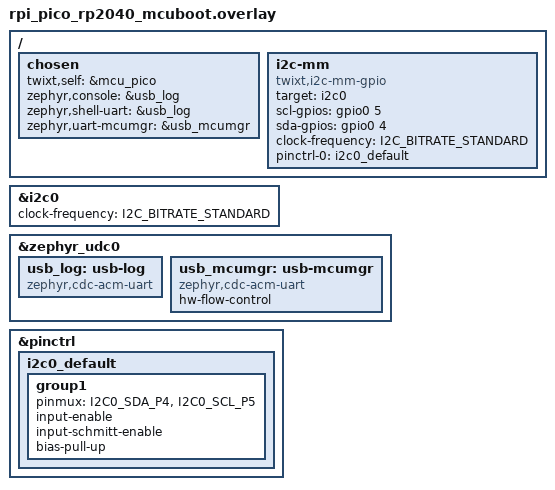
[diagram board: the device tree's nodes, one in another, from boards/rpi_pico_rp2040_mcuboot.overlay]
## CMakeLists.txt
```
# Copyright (c) 2026 Christoph Jans <jans.christoph@gmail.com>
# SPDX-License-Identifier: Apache-2.0

cmake_minimum_required(VERSION 3.20.0)

# native_sim: MCU says which one this is. Real boards: the overlay.
set(MCU pico CACHE STRING "MCU to build on native_sim: pico or nrf")
list(APPEND DTS_EXTRA_CPPFLAGS -DTWIXT_SELF_LABEL=mcu_${MCU})

find_package(Zephyr REQUIRED HINTS $ENV{ZEPHYR_BASE})
project(twixt_settings)

target_sources(app PRIVATE src/main.c)
target_sources_ifdef(CONFIG_USB_DEVICE_STACK_NEXT app PRIVATE src/usb.c)
```

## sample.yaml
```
# Copyright (c) 2026 Christoph Jans <jans.christoph@gmail.com>
# SPDX-License-Identifier: Apache-2.0

sample:
  name: Settings over twixt
common:
  tags:
    - i2c
    - settings
tests:
  # MCU a, started by twister; pytest/test_settings.py starts b next to it
  sample.twixt.settings:
    platform_allow: native_sim
    integration_platforms:
      - native_sim
    extra_args: MCU=a
    harness: pytest
    required_applications:
      - name: sample.twixt.settings.mcu_b
  sample.twixt.settings.mcu_b:
    platform_allow: native_sim
    extra_args: MCU=b
    build_only: true
  # On real boards (README): b on an nRF7002 DK, the DUT, and a on a Raspberry
  # Pico; with --device-testing, twister flashes both and pytest/test_settings.py
  # reads both logs
  sample.twixt.settings.nrf7002dk:
    platform_allow: nrf7002dk/nrf5340/cpuapp
    integration_platforms:
      - nrf7002dk/nrf5340/cpuapp
    extra_args: MCU=b
    harness: pytest
    harness_config:
      required_devices:
        - platform: rpi_pico/rp2040/mcuboot
          application: sample.twixt.settings.rpi_pico
  # a on the Pico: the image alone, signed for the MCUboot that is on the Pico
  # (README), so that the smp runner can send it over MCUmgr
  sample.twixt.settings.rpi_pico:
    platform_allow: rpi_pico/rp2040/mcuboot
    integration_platforms:
      - rpi_pico/rp2040/mcuboot
    extra_args: MCU=a
    extra_configs:
      - CONFIG_BOOTLOADER_MCUBOOT=y
      - CONFIG_MCUBOOT_BOOTLOADER_MODE_SWAP_USING_OFFSET=y
      - CONFIG_MCUBOOT_SIGNATURE_KEY_FILE="bootloader/mcuboot/root-rsa-2048.pem"
    build_only: true
```

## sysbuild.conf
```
# Copyright (c) 2026 Christoph Jans <jans.christoph@gmail.com>
# SPDX-License-Identifier: Apache-2.0

# MCUboot: the image updates itself over MCUmgr on USB
SB_CONFIG_BOOTLOADER_MCUBOOT=y
```

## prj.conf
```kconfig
# Copyright (c) 2026 Christoph Jans <jans.christoph@gmail.com>
# SPDX-License-Identifier: Apache-2.0

CONFIG_I2C=y
CONFIG_LOG=y
CONFIG_LOG_BACKEND_SHOW_COLOR=n

# Settings in NVS
CONFIG_FLASH=y
CONFIG_FLASH_MAP=y
CONFIG_NVS=y
CONFIG_SETTINGS=y
CONFIG_SETTINGS_NVS=y
CONFIG_TWIXT_SETTINGS=y
CONFIG_TWIXT_SETTINGS_VALUE_MAX=32
CONFIG_MAIN_STACK_SIZE=2048
CONFIG_SYSTEM_WORKQUEUE_STACK_SIZE=2048
CONFIG_NVS_LOG_LEVEL_WRN=y
```

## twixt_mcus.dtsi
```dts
/*
 * Copyright (c) 2026 Christoph Jans <jans.christoph@gmail.com>
 *
 * SPDX-License-Identifier: Apache-2.0
 */

mcu_pico: pico@10 {
	compatible = "twixt,mcu";
	reg = <0x10>;
};

mcu_nrf: nrf@11 {
	compatible = "twixt,mcu";
	reg = <0x11>;
};
```

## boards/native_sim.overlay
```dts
/*
 * Copyright (c) 2026 Christoph Jans <jans.christoph@gmail.com>
 *
 * SPDX-License-Identifier: Apache-2.0
 */

/ {
	chosen {
		twixt,self = &TWIXT_SELF_LABEL;
	};
};

&i2c0 {
	compatible = "twixt,i2c-mm-native";
	bus-id = <0>;

#include "../twixt_mcus.dtsi"
};
```

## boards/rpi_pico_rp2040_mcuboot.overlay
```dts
/*
 * Copyright (c) 2026 Christoph Jans <jans.christoph@gmail.com>
 *
 * SPDX-License-Identifier: Apache-2.0
 */

/* The bus on GP4 (pin 6), GP5 (pin 7), at 3.3 V: I2C0 is the target, the controller software on
 * the same pins (twixt,i2c-mm-gpio). pinctrl-0 gives the pins back to I2C0.
 */

#include <zephyr/dt-bindings/i2c/i2c.h>

/ {
	chosen {
		twixt,self = &mcu_pico;
		zephyr,console = &usb_log;
		zephyr,shell-uart = &usb_log;
		zephyr,uart-mcumgr = &usb_mcumgr;
	};

	i2c-mm {
		compatible = "twixt,i2c-mm-gpio";
		target = <&i2c0>;
		scl-gpios = <&gpio0 5 0>;
		sda-gpios = <&gpio0 4 0>;
		clock-frequency = <I2C_BITRATE_STANDARD>;
		pinctrl-0 = <&i2c0_default>;
		pinctrl-names = "default";
		#address-cells = <1>;
		#size-cells = <0>;

#include "../twixt_mcus.dtsi"
	};
};

&i2c0 {
	clock-frequency = <I2C_BITRATE_STANDARD>;
};

&zephyr_udc0 {
	usb_log: usb-log {
		compatible = "zephyr,cdc-acm-uart";
	};

	usb_mcumgr: usb-mcumgr {
		compatible = "zephyr,cdc-acm-uart";
		/* poll_out: wait instead of dropping */
		hw-flow-control;
	};
};

&pinctrl {
	i2c0_default: i2c0_default {
		group1 {
			pinmux = <I2C0_SDA_P4>, <I2C0_SCL_P5>;
			input-enable;
			input-schmitt-enable;
			bias-pull-up; /* weak; the bus needs its own pull-ups */
		};
	};
};
```

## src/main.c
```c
/*
 * Copyright (c) 2026 Christoph Jans <jans.christoph@gmail.com>
 *
 * SPDX-License-Identifier: Apache-2.0
 *
 * Settings over twixt: one MCU of two. It serves its settings (Zephyr
 * settings subsystem, subtree "mcu") to the other MCU, and gets and sets those
 * of the other one by name (twixt/service/settings.h):
 *
 *   mcu/name       read-only   the devicetree node of the MCU
 *   mcu/greeting   read/write  any text, kept in flash
 */

#include <stdio.h>
#include <string.h>
#include <zephyr/kernel.h>
#include <zephyr/logging/log.h>
#include <zephyr/settings/settings.h>
#include <zephyr/spinlock.h>

#include <twixt/twixt.h>
#include <twixt/service/ping.h>
#include <twixt/service/settings.h>

LOG_MODULE_REGISTER(settings_sample, LOG_LEVEL_INF);

/*
 * The other MCU's requests run in the I2C target interrupt, and so do these
 * handlers: static, short, and the greeting under a spinlock
 */
static struct k_spinlock lock;
static char greeting[TWIXT_SETTINGS_VALUE_MAX];
static size_t greeting_len;

static int mcu_get(const char *key, char *val, int val_len_max)
{
	int len = -ENOENT;

	if (settings_name_steq(key, "name", NULL)) {
		len = strlen(twixt_self_name());
		memcpy(val, twixt_self_name(), MIN(len, val_len_max));
	} else if (settings_name_steq(key, "greeting", NULL)) {
		K_SPINLOCK(&lock) {
			len = greeting_len;
			memcpy(val, greeting, MIN(len, val_len_max));
		}
	}
	return len;
}

static int mcu_set(const char *key, size_t len, settings_read_cb read_cb, void *cb_arg)
{
	char val[sizeof(greeting)];
	ssize_t ret;

	if (settings_name_steq(key, "name", NULL)) {
		return -EACCES;
	}
	if (!settings_name_steq(key, "greeting", NULL)) {
		return -ENOENT;
	}
	if (len > sizeof(val)) {
		return -EINVAL;
	}
	ret = read_cb(cb_arg, val, len);
	if (ret < 0) {
		return ret;
	}
	K_SPINLOCK(&lock) {
		memcpy(greeting, val, len);
		greeting_len = len;
	}
	return 0;
}

static int mcu_export(int (*export_func)(const char *name, const void *val, size_t val_len))
{
	char val[sizeof(greeting)];
	size_t len;

	K_SPINLOCK(&lock) {
		len = greeting_len;
		memcpy(val, greeting, len);
	}
	return len > 0 ? export_func("mcu/greeting", val, len) : 0;
}

SETTINGS_STATIC_HANDLER_DEFINE(mcu, "mcu", mcu_get, mcu_set, NULL, mcu_export);

#define ADDR(node) DT_REG_ADDR(node),
static const uint8_t mcus[] = {DT_FOREACH_STATUS_OKAY(twixt_mcu, ADDR)};

static uint8_t other_mcu(void)
{
	return mcus[0] != twixt_self_addr() ? mcus[0] : mcus[1];
}

int main(void)
{
	uint8_t peer = other_mcu();
	struct twixt_ping_info info;
	char val[TWIXT_SETTINGS_VALUE_MAX];
	char hi[TWIXT_SETTINGS_VALUE_MAX];
	int len;
	int ret;

	BUILD_ASSERT(ARRAY_SIZE(mcus) == 2, "this sample is for two MCUs");

	ret = settings_subsys_init();
	if (ret == 0) {
		ret = settings_load();
	}
	if (ret) {
		LOG_ERR("cannot load the settings: %d", ret);
		return 0;
	}
	LOG_INF("%s at 0x%02x, greeting from flash: \"%.*s\"", twixt_self_name(), twixt_self_addr(),
		(int)greeting_len, greeting);

	while (true) {
		k_sleep(K_SECONDS(5));

		ret = twixt_ping_wait(peer, &info, K_SECONDS(1));
		if (ret) {
			LOG_ERR("no answer from 0x%02x: %d", peer, ret);
			continue;
		}

		len = twixt_settings_get(peer, "mcu/name", val, sizeof(val));
		if (len < 0) {
			LOG_ERR("get mcu/name of 0x%02x: %d", peer, len);
			continue;
		}
		LOG_INF("0x%02x is %.*s", peer, MIN(len, (int)sizeof(val)), val);

		len = snprintf(hi, sizeof(hi), "hi from %s", twixt_self_name());
		ret = twixt_settings_set(peer, "mcu/greeting", hi, MIN(len, (int)sizeof(hi) - 1));
		if (ret) {
			LOG_ERR("set mcu/greeting of 0x%02x: %d", peer, ret);
			continue;
		}

		len = twixt_settings_get(peer, "mcu/greeting", val, sizeof(val));
		if (len < 0) {
			LOG_ERR("get mcu/greeting of 0x%02x: %d", peer, len);
			continue;
		}
		LOG_INF("0x%02x mcu/greeting = \"%.*s\"", peer, MIN(len, (int)sizeof(val)), val);

		ret = twixt_settings_set(peer, "mcu/name", "x", 1);
		LOG_INF("0x%02x mcu/name is read-only: %d", peer, ret);
	}

	return 0;
}
```
